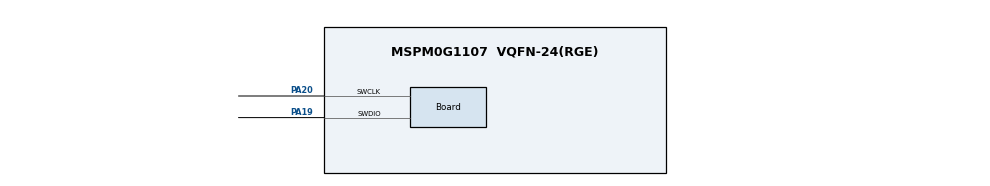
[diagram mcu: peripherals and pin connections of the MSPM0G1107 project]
/**
 * These arguments were used when this file was generated. They will be automatically applied on subsequent loads
 * via the GUI or CLI. Run CLI with '--help' for additional information on how to override these arguments.
 * @cliArgs --device "MSPM0G110X" --part "Default" --package "VQFN-24(RGE)" --product "mspm0_sdk@2.04.00.06"
 * @v2CliArgs --device "MSPM0G1107" --package "VQFN-24(RGE)" --product "mspm0_sdk@2.04.00.06"
 * @versions {"tool":"1.22.0+3893"}
 */

/**
 * Import the modules used in this configuration.
 */
const ADC12         = scripting.addModule("/ti/driverlib/ADC12", {}, false);
const ADC121        = ADC12.addInstance();
const SYSCTL        = scripting.addModule("/ti/driverlib/SYSCTL");
const VREF          = scripting.addModule("/ti/driverlib/VREF");
const ProjectConfig = scripting.addModule("/ti/project_config/ProjectConfig");

/**
 * Write custom configuration values to the imported modules.
 */
const multiplier2         = system.clockTree["PLL_QDIV"];
multiplier2.multiplyValue = 5;

ADC121.$name          = "ADC12_0";
ADC121.sampClkDiv     = "DL_ADC12_CLOCK_DIVIDE_4";
ADC121.repeatMode     = true;
ADC121.adcMem0chansel = "DL_ADC12_INPUT_CHAN_15";
ADC121.adcMem0vref    = "VREF";

const Board                       = scripting.addModule("/ti/driverlib/Board", {}, false);
Board.peripheral.$assign          = "DEBUGSS";
Board.peripheral.swclkPin.$assign = "PA20";
Board.peripheral.swdioPin.$assign = "PA19";

SYSCTL.peripheral.$assign = "SYSCTL";

VREF.vrefPosPinConfig.$name = "ti_driverlib_gpio_GPIOPinGeneric0";

ProjectConfig.migrationCondition = true;

/**
 * Pinmux solution for unlocked pins/peripherals. This ensures that minor changes to the automatic solver in a future
 * version of the tool will not impact the pinmux you originally saw.  These lines can be completely deleted in order to
 * re-solve from scratch.
 */
ADC121.peripheral.$suggestSolution          = "ADC0";
VREF.peripheral.$suggestSolution            = "VREF";
VREF.peripheral.vrefPosPin.$suggestSolution = "PA23";
